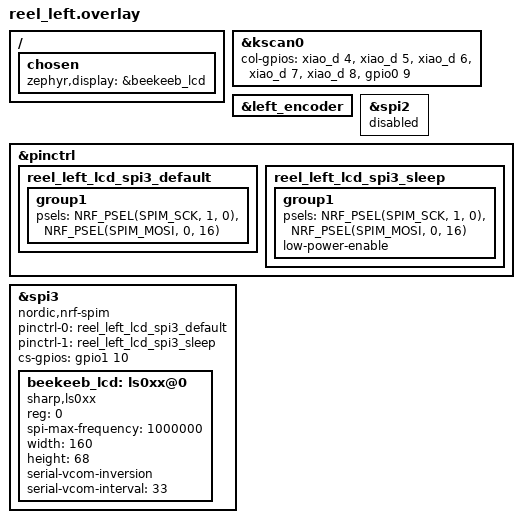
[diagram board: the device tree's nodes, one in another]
#include "reel.dtsi"
#include <zephyr/dt-bindings/pinctrl/nrf-pinctrl.h>

&kscan0 {
    col-gpios
        = <&xiao_d 4 GPIO_ACTIVE_HIGH>
        , <&xiao_d 5 GPIO_ACTIVE_HIGH>
        , <&xiao_d 6 GPIO_ACTIVE_HIGH>
        , <&xiao_d 7 GPIO_ACTIVE_HIGH>
        , <&xiao_d 8 GPIO_ACTIVE_HIGH>
        , <&gpio0 9 GPIO_ACTIVE_HIGH>
        ;
};

&left_encoder {
    status = "okay";
};

&spi2 {
    status = "disabled";
};

&pinctrl {
    reel_left_lcd_spi3_default: reel_left_lcd_spi3_default {
        group1 {
            psels = <NRF_PSEL(SPIM_SCK, 1, 0)>,
                    <NRF_PSEL(SPIM_MOSI, 0, 16)>;
        };
    };

    reel_left_lcd_spi3_sleep: reel_left_lcd_spi3_sleep {
        group1 {
            psels = <NRF_PSEL(SPIM_SCK, 1, 0)>,
                    <NRF_PSEL(SPIM_MOSI, 0, 16)>;
            low-power-enable;
        };
    };
};

/*
 * Left-side LS011B7DH03:
 * SI=P0.16, SCK=P1.00, CS=P1.10. Serial VCOM inversion means no
 * separate EXTCOMIN signal is required.
 */
&spi3 {
    compatible = "nordic,nrf-spim";
    status = "okay";
    pinctrl-0 = <&reel_left_lcd_spi3_default>;
    pinctrl-1 = <&reel_left_lcd_spi3_sleep>;
    pinctrl-names = "default", "sleep";
    cs-gpios = <&gpio1 10 GPIO_ACTIVE_HIGH>;

    beekeeb_lcd: ls0xx@0 {
        compatible = "sharp,ls0xx";
        reg = <0>;
        spi-max-frequency = <1000000>;
        width = <160>;
        height = <68>;
        serial-vcom-inversion;
        serial-vcom-interval = <33>;
    };
};

/ {
    chosen {
        zephyr,display = &beekeeb_lcd;
    };
};
